# t register map
Registers are 32-bit, access not given, reset 0x1 unless marked. A register's access mark holds for its fields unless they carry their own. Offsets are from the block's base; lines under a group give offsets from that group; [hi:lo] are bit positions; {n}, {i} and the like mark numbered series; 'fields as' and 'values as' point back to an identical list; <NAME> marks a mode.

## Memory map
0x40000000 CAN0

## CAN0
Base 0x40000000
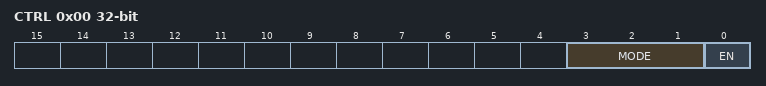
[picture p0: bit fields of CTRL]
0x00 CTRL
  [3:1] MODE
    0=NORMAL; 2=LOOP
  [0] EN
